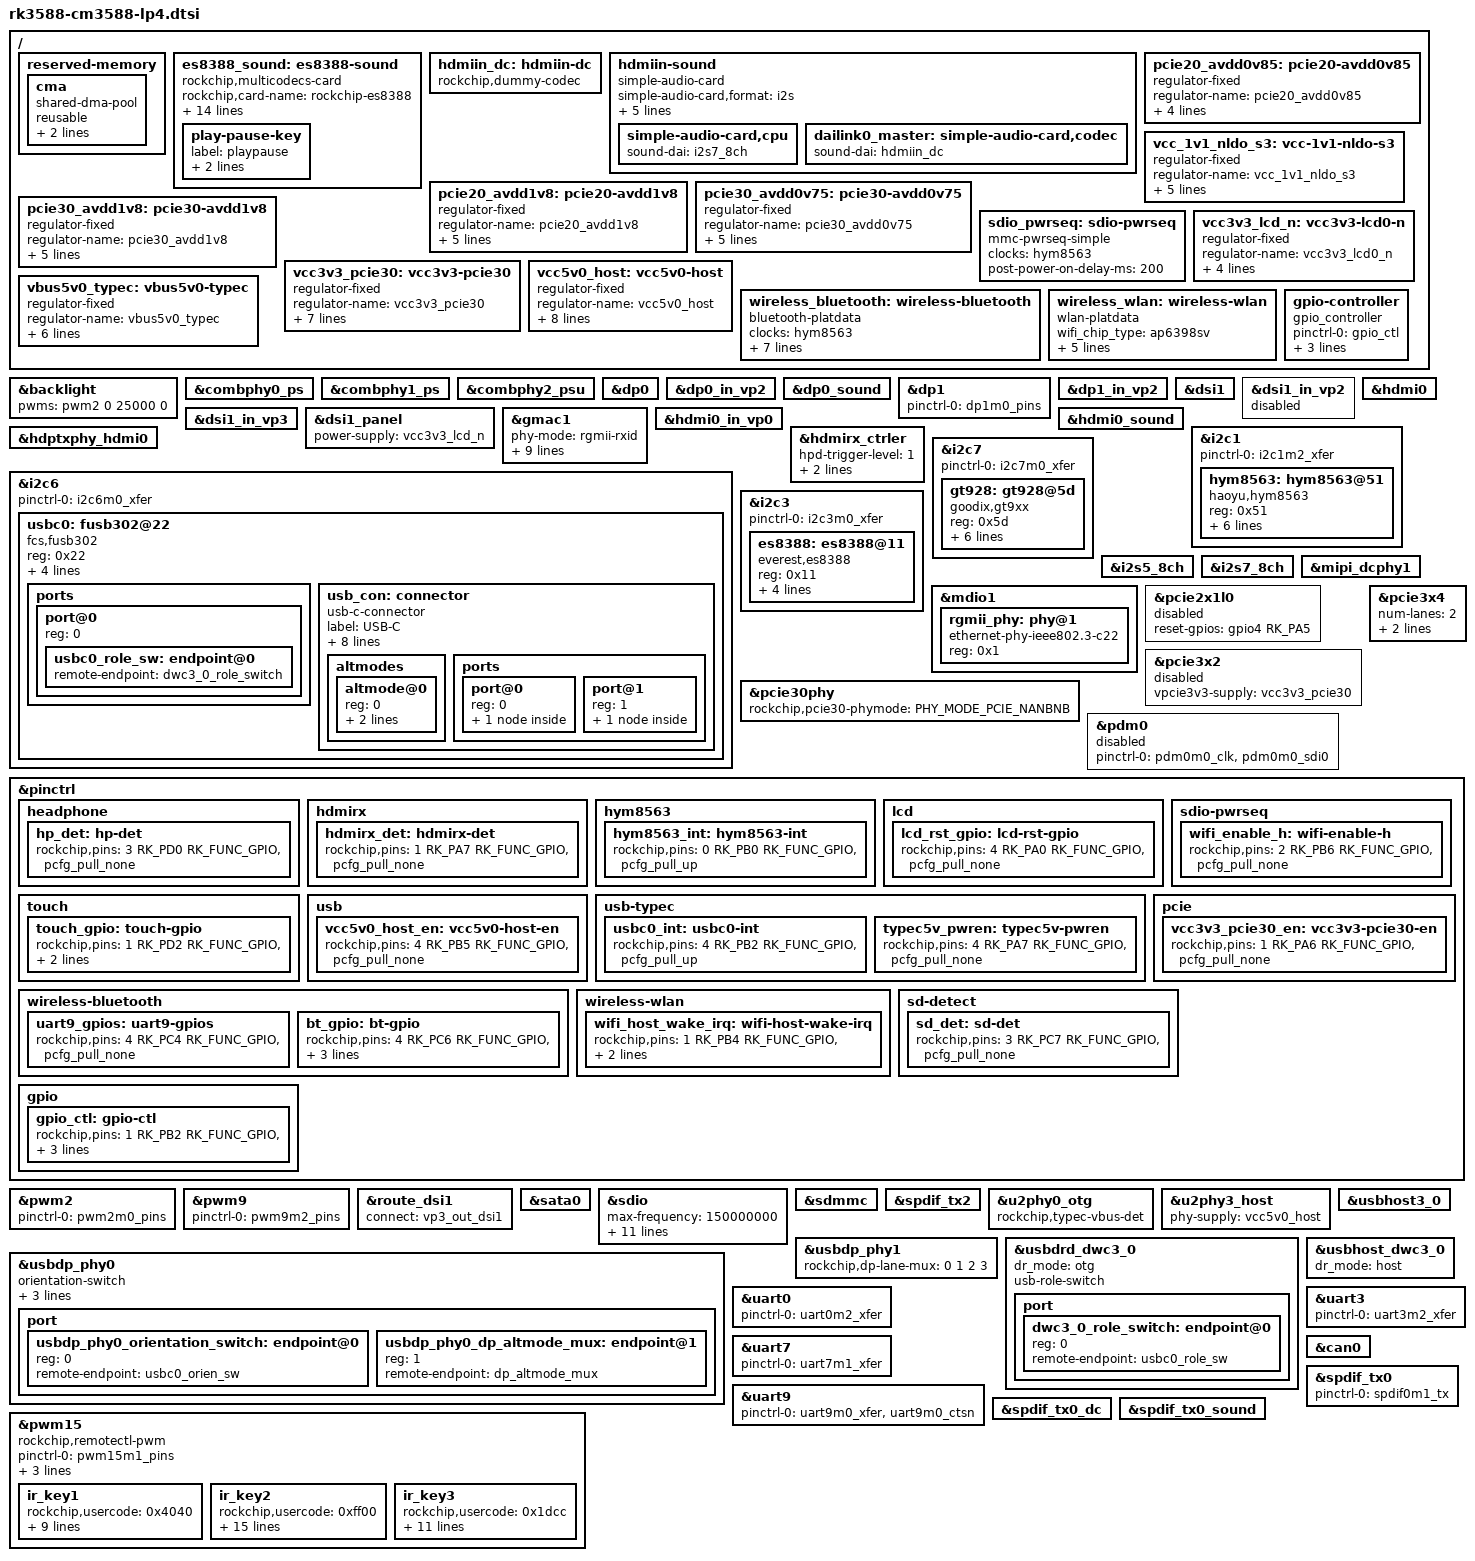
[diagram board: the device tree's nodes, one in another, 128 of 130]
// SPDX-License-Identifier: (GPL-2.0+ OR MIT)
/*
 * Copyright (c) 2021 Rockchip Electronics Co., Ltd.
 *
 */
#include "dt-bindings/usb/pd.h"
#include "rk3588.dtsi"
#include "rk3588-cm3588.dtsi"
#include "rk3588-cm3588-rk806-single.dtsi"

/ {
	/* If hdmirx node is disabled, delete the reserved-memory node here. */
	reserved-memory {
		#address-cells = <2>;
		#size-cells = <2>;
		ranges;

		/* Reserve 256MB memory for hdmirx-controller@fdee0000 */
		cma {
			compatible = "shared-dma-pool";
			reusable;
			reg = <0x0 (256 * 0x100000) 0x0 (256 * 0x100000)>;
			linux,cma-default;
		};
	};
	es8388_sound: es8388-sound {
		status = "okay";
		compatible = "rockchip,multicodecs-card";
		rockchip,card-name = "rockchip-es8388";
	//	hp-det-gpio = <&gpio3 RK_PD0 GPIO_ACTIVE_HIGH>;
		io-channels = <&saradc 5>;
		io-channel-names = "adc-detect";
		keyup-threshold-microvolt = <1800000>;
		poll-interval = <100>;
		//spk-con-gpio = <&gpio1 RK_PD3 GPIO_ACTIVE_HIGH>;
		//hp-con-gpio = <&gpio1 RK_PD2 GPIO_ACTIVE_HIGH>;
		rockchip,format = "i2s";
		rockchip,mclk-fs = <256>;
		rockchip,cpu = <&i2s0_8ch>;
		rockchip,codec = <&es8388>;
		rockchip,audio-routing =
			"Headphone", "LOUT1",
			"Headphone", "ROUT1",
			"Speaker", "LOUT2",
			"Speaker", "ROUT2",
			"Headphone", "Headphone Power",
			"Headphone", "Headphone Power",
			"Speaker", "Speaker Power",
			"Speaker", "Speaker Power",
			"LINPUT1", "Main Mic",
			"LINPUT2", "Main Mic",
			"RINPUT1", "Headset Mic",
			"RINPUT2", "Headset Mic";
	//	pinctrl-names = "default";
	//	pinctrl-0 = <&hp_det>;
		play-pause-key {
			label = "playpause";
			linux,code = <KEY_PLAYPAUSE>;
			press-threshold-microvolt = <2000>;
		};
	};

	hdmiin_dc: hdmiin-dc {
		compatible = "rockchip,dummy-codec";
		#sound-dai-cells = <0>;
	};

	hdmiin-sound {
		compatible = "simple-audio-card";
		simple-audio-card,format = "i2s";
		simple-audio-card,name = "rockchip,hdmiin";
		simple-audio-card,bitclock-master = <&dailink0_master>;
		simple-audio-card,frame-master = <&dailink0_master>;
		status = "okay";
		simple-audio-card,cpu {
			sound-dai = <&i2s7_8ch>;
		};
		dailink0_master: simple-audio-card,codec {
			sound-dai = <&hdmiin_dc>;
		};
	};
	pcie20_avdd0v85: pcie20-avdd0v85 {
		compatible = "regulator-fixed";
		regulator-name = "pcie20_avdd0v85";
		regulator-boot-on;
		regulator-always-on;
		regulator-min-microvolt = <850000>;
		regulator-max-microvolt = <850000>;
	//	vin-supply = <&avdd_0v85_s0>;
	};
	vcc_1v1_nldo_s3: vcc-1v1-nldo-s3 {
		compatible = "regulator-fixed";
		regulator-name = "vcc_1v1_nldo_s3";
		regulator-always-on;
		regulator-boot-on;
		regulator-min-microvolt = <1100000>;
		regulator-max-microvolt = <1100000>;
		vin-supply = <&vcc5v0_sys>;
	};
	pcie20_avdd1v8: pcie20-avdd1v8 {
		compatible = "regulator-fixed";
		regulator-name = "pcie20_avdd1v8";
		regulator-boot-on;
		regulator-always-on;
		regulator-min-microvolt = <1800000>;
		regulator-max-microvolt = <1800000>;
		vin-supply = <&avcc_1v8_s0>;
	};

	pcie30_avdd0v75: pcie30-avdd0v75 {
		compatible = "regulator-fixed";
		regulator-name = "pcie30_avdd0v75";
		regulator-boot-on;
		regulator-always-on;
		regulator-min-microvolt = <750000>;
		regulator-max-microvolt = <750000>;
		vin-supply = <&avdd_0v75_s0>;
	};

	pcie30_avdd1v8: pcie30-avdd1v8 {
		compatible = "regulator-fixed";
		regulator-name = "pcie30_avdd1v8";
		regulator-boot-on;
		regulator-always-on;
		regulator-min-microvolt = <1800000>;
		regulator-max-microvolt = <1800000>;
		vin-supply = <&avcc_1v8_s0>;
	};

	sdio_pwrseq: sdio-pwrseq {
		compatible = "mmc-pwrseq-simple";
		clocks = <&hym8563>;
		clock-names = "ext_clock";
		//pinctrl-names = "default";
		//pinctrl-0 = <&wifi_enable_h>;
		/*
		 * On the module itself this is one of these (depending
		 * on the actual card populated):
		 * - SDIO_RESET_L_WL_REG_ON
		 * - PDN (power down when low)
		 */
		post-power-on-delay-ms = <200>;
		//reset-gpios = <&gpio2 RK_PB6 GPIO_ACTIVE_LOW>;
	};

	vcc3v3_lcd_n: vcc3v3-lcd0-n {
		compatible = "regulator-fixed";
		regulator-name = "vcc3v3_lcd0_n";
		regulator-boot-on;
		enable-active-high;
		gpio = <&gpio1 RK_PC4 GPIO_ACTIVE_HIGH>;
		vin-supply = <&vcc_1v8_s0>;
	};

	vcc3v3_pcie30: vcc3v3-pcie30 {
		compatible = "regulator-fixed";
		regulator-name = "vcc3v3_pcie30";
		regulator-min-microvolt = <3300000>;
		regulator-max-microvolt = <3300000>;
		enable-active-high;
		gpios = <&gpio1 RK_PA6 GPIO_ACTIVE_HIGH>;
		startup-delay-us = <5000>;
		vin-supply = <&vcc12v_dcin>;
		pinctrl-names = "default";
		pinctrl-0 = <&vcc3v3_pcie30_en>;
	};

	vcc5v0_host: vcc5v0-host {
		compatible = "regulator-fixed";
		regulator-name = "vcc5v0_host";
		regulator-boot-on;
		regulator-always-on;
		regulator-min-microvolt = <5000000>;
		regulator-max-microvolt = <5000000>;
		enable-active-high;
		gpio = <&gpio4 RK_PB5 GPIO_ACTIVE_HIGH>;
		vin-supply = <&vcc5v0_usb>;
		pinctrl-names = "default";
		pinctrl-0 = <&vcc5v0_host_en>;
	};

	vbus5v0_typec: vbus5v0-typec {
		compatible = "regulator-fixed";
		regulator-name = "vbus5v0_typec";
		regulator-min-microvolt = <5000000>;
		regulator-max-microvolt = <5000000>;
		enable-active-high;
		gpio = <&gpio4 RK_PA7 GPIO_ACTIVE_HIGH>;
		vin-supply = <&vcc5v0_usb>;
		pinctrl-names = "default";
		pinctrl-0 = <&typec5v_pwren>;
	};

	wireless_bluetooth: wireless-bluetooth {
		compatible = "bluetooth-platdata";
		clocks = <&hym8563>;
		clock-names = "ext_clock";
		uart_rts_gpios = <&gpio4 RK_PC4 GPIO_ACTIVE_LOW>;
		pinctrl-names = "default", "rts_gpio";
		pinctrl-0 = <&uart9m0_rtsn>, <&bt_gpio>;
		pinctrl-1 = <&uart9_gpios>;
		BT,reset_gpio    = <&gpio4 RK_PC6 GPIO_ACTIVE_HIGH>;
		BT,wake_gpio     = <&gpio2 RK_PB6 GPIO_ACTIVE_HIGH>;
		BT,wake_host_irq = <&gpio2 RK_PC1 GPIO_ACTIVE_HIGH>;
		status = "okay";
	};

	wireless_wlan: wireless-wlan {
		compatible = "wlan-platdata";
		wifi_chip_type = "ap6398sv";//"ap6398s";
		pinctrl-names = "default";
		pinctrl-0 = <&wifi_host_wake_irq>;
		WIFI,host_wake_irq = <&gpio4 RK_PC2 GPIO_ACTIVE_HIGH>;
		WIFI,poweren_gpio = <&gpio1 RK_PB4 GPIO_ACTIVE_HIGH>;
		status = "okay";
	};

	gpio-controller{
		compatible = "gpio_controller";
		pinctrl-names = "default";
		pinctrl-0 = <&gpio_ctl>;
		mini4g_en = <&gpio1 RK_PB2 GPIO_ACTIVE_HIGH>;
		sata_en = <&gpio1 RK_PB3 GPIO_ACTIVE_HIGH>;
		fan_en = <&gpio3 RK_PD4 GPIO_ACTIVE_HIGH>;
		status = "okay";
	};
};

&backlight {
	pwms = <&pwm2 0 25000 0>;
	status = "okay";
};

&combphy0_ps {
	status = "okay";
};

&combphy1_ps {
	status = "okay";
};

&combphy2_psu {
	status = "okay";
};

&dp0 {
	//pinctrl-0 = <&dp0m2_pins>;
	pinctrl-names = "default";
	status = "okay";
};

&dp0_in_vp2 {
	status = "okay";
};

&dp0_sound {
	status = "okay";
};

&dp1 {
	pinctrl-0 = <&dp1m0_pins>;
	pinctrl-names = "default";
	status = "okay";
};

&dp1_in_vp2 {
	status = "okay";
};

/*
 * mipi_dcphy1 needs to be enabled
 * when dsi1 is enabled
 */
&dsi1 {
	status = "okay";
};

&dsi1_in_vp2 {
	status = "disabled";
};

&dsi1_in_vp3 {
	status = "okay";
};

&dsi1_panel {
	power-supply = <&vcc3v3_lcd_n>;
};

&gmac1 {
	/* Use rgmii-rxid mode to disable rx delay inside Soc */
	phy-mode = "rgmii-rxid";
	clock_in_out = "output";

	snps,reset-gpio = <&gpio0 RK_PC5 GPIO_ACTIVE_LOW>;
	snps,reset-active-low;
	/* Reset time is 20ms, 100ms for rtl8211f */
	snps,reset-delays-us = <0 20000 100000>;

	pinctrl-names = "default";
	pinctrl-0 = <&gmac1_miim
		     &gmac1_tx_bus2
		     &gmac1_rx_bus2
		     &gmac1_rgmii_clk
		     &gmac1_rgmii_bus>;

	tx_delay = <0x45>;
	/* rx_delay = <0x3f>; */

	phy-handle = <&rgmii_phy>;
	status = "okay";
};

&hdmi0 {
	//enable-gpios = <&gpio3 RK_PC5 GPIO_ACTIVE_HIGH>;
	status = "okay";
};

&hdmi0_in_vp0 {
	status = "okay";
};

&hdmi0_sound {
	status = "okay";
};


&hdptxphy_hdmi0 {
	status = "okay";
};

/* Should work with at least 128MB cma reserved above. */
&hdmirx_ctrler {
	status = "okay";

	/* Effective level used to trigger HPD: 0-low, 1-high */
	hpd-trigger-level = <1>;
	hdmirx-det-gpios = <&gpio1 RK_PA7 GPIO_ACTIVE_LOW>;
	pinctrl-names = "default";
	pinctrl-0 = <&hdmirx_det>;
};

&i2c1 {
	status = "okay";
	pinctrl-names = "default";
	pinctrl-0 = <&i2c1m2_xfer>;

	hym8563: hym8563@51 {
	status = "okay";
		compatible = "haoyu,hym8563";
		reg = <0x51>;
		#clock-cells = <0>;
		clock-frequency = <32768>;
		clock-output-names = "hym8563";
		pinctrl-names = "default";
		pinctrl-0 = <&hym8563_int>;
		interrupt-parent = <&gpio0>;
		interrupts = <RK_PB0 IRQ_TYPE_LEVEL_LOW>;
		wakeup-source;
	};
};

&i2c6 {
	status = "okay";
	pinctrl-names = "default";
	pinctrl-0 = <&i2c6m0_xfer>;
	usbc0: fusb302@22 {
		compatible = "fcs,fusb302";
		reg = <0x22>;
		interrupt-parent = <&gpio4>;
		interrupts = <RK_PB2 IRQ_TYPE_LEVEL_LOW>;
		pinctrl-names = "default";
		pinctrl-0 = <&usbc0_int>;
		vbus-supply = <&vbus5v0_typec>;
		status = "okay";

		ports {
			#address-cells = <1>;
			#size-cells = <0>;

			port@0 {
				reg = <0>;
				usbc0_role_sw: endpoint@0 {
					remote-endpoint = <&dwc3_0_role_switch>;
				};
			};
		};

		usb_con: connector {
			compatible = "usb-c-connector";
			label = "USB-C";
			data-role = "dual";
			power-role = "dual";
			try-power-role = "sink";
			op-sink-microwatt = <1000000>;
			sink-pdos = <PDO_FIXED(5000, 1000, PDO_FIXED_USB_COMM)>;
			source-pdos = <PDO_FIXED(5000, 3000, PDO_FIXED_USB_COMM)>;

			altmodes {
				#address-cells = <1>;
				#size-cells = <0>;

				altmode@0 {
					reg = <0>;
					svid = <0xff01>;
					vdo = <0xffffffff>;
				};
			};

			ports {
				#address-cells = <1>;
				#size-cells = <0>;

				port@0 {
					reg = <0>;
					usbc0_orien_sw: endpoint {
						remote-endpoint = <&usbdp_phy0_orientation_switch>;
					};
				};

				port@1 {
					reg = <1>;
					dp_altmode_mux: endpoint {
						remote-endpoint = <&usbdp_phy0_dp_altmode_mux>;
					};
				};
			};
		};
	};
};

&i2c7 {
	status = "okay";
	pinctrl-names = "default";
	pinctrl-0 = <&i2c7m0_xfer>;

		gt928: gt928@5d {
		status = "okay";
		compatible = "goodix,gt9xx";
		reg = <0x5d>;
		max-x = <1280>;
		max-y = <800>;
		tp-size = <89>;
		pinctrl-names = "default";
		pinctrl-0 = <&touch_gpio>;
		touch-gpio = <&gpio1 RK_PD3 GPIO_ACTIVE_LOW>;
		reset-gpio = <&gpio1 RK_PD2 GPIO_ACTIVE_LOW>;
	};
};

&i2c3 {
	status = "okay";
	pinctrl-names = "default";
	pinctrl-0 = <&i2c3m0_xfer>;

	es8388: es8388@11 {
		status = "okay";
		#sound-dai-cells = <0>;
		compatible = "everest,es8388", "everest,es8323";
		reg = <0x11>;
		clocks = <&cru I2S0_8CH_MCLKOUT>;
		clock-names = "mclk";
		assigned-clocks = <&cru I2S0_8CH_MCLKOUT>;
		assigned-clock-rates = <12288000>;
		pinctrl-names = "default";
		pinctrl-0 = <&i2s0_mclk>;
	};

};

&i2s5_8ch {
	status = "okay";
};

&i2s7_8ch {
	status = "okay";
};

&mdio1 {
	rgmii_phy: phy@1 {
		compatible = "ethernet-phy-ieee802.3-c22";
		reg = <0x1>;
	};
};

&mipi_dcphy1 {
	status = "okay";
};


&pcie2x1l0 {
	reset-gpios = <&gpio4 RK_PA5 GPIO_ACTIVE_HIGH>;
	status = "disabled";
};

&pcie30phy {
	rockchip,pcie30-phymode = <PHY_MODE_PCIE_NANBNB>;
	status = "okay";
};

&pcie3x2 {
	//reset-gpios = <&gpio4 RK_PB6 GPIO_ACTIVE_HIGH>;
	vpcie3v3-supply = <&vcc3v3_pcie30>;
	status = "disabled";
};

&pcie3x4 {
	num-lanes = <2>;
	//reset-gpios = <&gpio4 RK_PB6 GPIO_ACTIVE_HIGH>;
	reset-gpios = <&gpio3 RK_PC6 GPIO_ACTIVE_HIGH>;
	vpcie3v3-supply = <&vcc3v3_pcie30>;
	status = "okay";
};

&pdm0 {
	status = "disabled";
	pinctrl-names = "default";
	pinctrl-0 = <&pdm0m0_clk
		     &pdm0m0_sdi0>;
};

&pinctrl {
	headphone {
		hp_det: hp-det {
			rockchip,pins = <3 RK_PD0 RK_FUNC_GPIO &pcfg_pull_none>;
		};
	};
	hdmirx{
		hdmirx_det: hdmirx-det{
			rockchip,pins = <1 RK_PA7 RK_FUNC_GPIO &pcfg_pull_none>;
			};
	};
	hym8563 {
		hym8563_int: hym8563-int {
			rockchip,pins = <0 RK_PB0 RK_FUNC_GPIO &pcfg_pull_up>;
		};
	};

	lcd {
		lcd_rst_gpio: lcd-rst-gpio {
			rockchip,pins = <4 RK_PA0 RK_FUNC_GPIO &pcfg_pull_none>;
		};
	};

	sdio-pwrseq {
		wifi_enable_h: wifi-enable-h {
		       rockchip,pins = <2 RK_PB6 RK_FUNC_GPIO &pcfg_pull_none>;
	       };
	};

	touch {
		touch_gpio: touch-gpio {
			rockchip,pins =
				<1 RK_PD2 RK_FUNC_GPIO &pcfg_pull_up>,
				<1 RK_PD3 RK_FUNC_GPIO &pcfg_pull_none>;
		};
	};

	usb {
		vcc5v0_host_en: vcc5v0-host-en {
			rockchip,pins = <4 RK_PB5 RK_FUNC_GPIO &pcfg_pull_none>;
		};
	};
	usb-typec {
		usbc0_int: usbc0-int {
			rockchip,pins = <4 RK_PB2 RK_FUNC_GPIO &pcfg_pull_up>;
		};

		typec5v_pwren: typec5v-pwren {
			rockchip,pins = <4 RK_PA7 RK_FUNC_GPIO &pcfg_pull_none>;
		};
	};

	pcie {
		vcc3v3_pcie30_en: vcc3v3-pcie30-en {
			rockchip,pins = <1 RK_PA6 RK_FUNC_GPIO &pcfg_pull_none>;
		};
	};

	wireless-bluetooth {
		uart9_gpios: uart9-gpios {
			rockchip,pins = <4 RK_PC4 RK_FUNC_GPIO &pcfg_pull_none>;
		};

		bt_gpio: bt-gpio {
			rockchip,pins =
				<4 RK_PC6 RK_FUNC_GPIO &pcfg_pull_none>,
				<2 RK_PB6 RK_FUNC_GPIO &pcfg_pull_up>,
				<2 RK_PC1 RK_FUNC_GPIO &pcfg_pull_down>;
		};
	};

	wireless-wlan {
		wifi_host_wake_irq: wifi-host-wake-irq {
			rockchip,pins =
				<1 RK_PB4 RK_FUNC_GPIO &pcfg_pull_up>,
				<4 RK_PC2 RK_FUNC_GPIO &pcfg_pull_down>;
		};
	};

	sd-detect {
		sd_det: sd-det {
		       rockchip,pins = <3 RK_PC7 RK_FUNC_GPIO &pcfg_pull_none>;
	       };
	};

	gpio {
		gpio_ctl: gpio-ctl {
			rockchip,pins =
				<1 RK_PB2 RK_FUNC_GPIO &pcfg_pull_up>,
				<3 RK_PD4 RK_FUNC_GPIO &pcfg_pull_up>,
				<1 RK_PB3 RK_FUNC_GPIO &pcfg_pull_up>;
		};
	};
};

&pwm2 {
	status = "okay";
	pinctrl-0 = <&pwm2m0_pins>;
};

&pwm9 {
	pinctrl-0 = <&pwm9m2_pins>;
	status = "okay";
};

&route_dsi1 {
	status = "okay";
	connect = <&vp3_out_dsi1>;
};

&sata0 {
	status = "okay";
};

&sdio {
	max-frequency = <150000000>;
	no-sd;
	no-mmc;
	bus-width = <4>;
	disable-wp;
	cap-sd-highspeed;
	cap-sdio-irq;
	keep-power-in-suspend;
	mmc-pwrseq = <&sdio_pwrseq>;
	non-removable;
	pinctrl-names = "default";
	pinctrl-0 = <&sdiom0_pins>;
	sd-uhs-sdr104;
	status = "okay";
};

&sdmmc {
	status = "okay";
//	vmmc-supply = <&vcc_3v3_sd_s0>;
/*	pinctrl-names = "default";
	pinctrl-0 = <&sd_det &sdmmc_clk &sdmmc_cmd &sdmmc_det &sdmmc_bus4>;
	cd-gpios = <&gpio3 RK_PC7 GPIO_ACTIVE_LOW>;
	cd-inverted;*/
};

&spdif_tx2 {
	status = "okay";
};

&u2phy0_otg {
	rockchip,typec-vbus-det;
};

&u2phy3_host {
	phy-supply = <&vcc5v0_host>;
};

/*&usbdp_phy0 {
	rockchip,dp-lane-mux = <2 3>;
};
*/
&usbdp_phy0 {
	orientation-switch;
	svid = <0xff01>;
	sbu1-dc-gpios = <&gpio0 RK_PC6 GPIO_ACTIVE_HIGH>;
	sbu2-dc-gpios = <&gpio0 RK_PD3 GPIO_ACTIVE_HIGH>;

	port {
		#address-cells = <1>;
		#size-cells = <0>;
		usbdp_phy0_orientation_switch: endpoint@0 {
			reg = <0>;
			remote-endpoint = <&usbc0_orien_sw>;
		};

		usbdp_phy0_dp_altmode_mux: endpoint@1 {
			reg = <1>;
			remote-endpoint = <&dp_altmode_mux>;
		};
	};
};

&usbdp_phy1 {
	rockchip,dp-lane-mux = <0 1 2 3>;
};

&usbdrd_dwc3_0 {
	dr_mode = "otg";
	usb-role-switch;
	port {
		#address-cells = <1>;
		#size-cells = <0>;
		dwc3_0_role_switch: endpoint@0 {
			reg = <0>;
			remote-endpoint = <&usbc0_role_sw>;
		};
	};
};

&usbhost3_0 {
	status = "okay";
};

&usbhost_dwc3_0 {
	dr_mode = "host";
	status = "okay";
};

&uart0 {
	status = "okay";
	pinctrl-names = "default";
	pinctrl-0 = <&uart0m2_xfer>;
};

&uart3 {
	status = "okay";
	pinctrl-names = "default";
	pinctrl-0 = <&uart3m2_xfer>;
};

&uart7 {
	status = "okay";
	pinctrl-names = "default";
	pinctrl-0 = <&uart7m1_xfer>;
};

&uart9 {
	status = "okay";
	pinctrl-names = "default";
	pinctrl-0 = <&uart9m0_xfer &uart9m0_ctsn>;
};

&can0 {
	status = "okay";
};

&vcc3v3_lcd_n {
	gpio = <&gpio1 RK_PC4 GPIO_ACTIVE_HIGH>;
	enable-active-high;
};

&spdif_tx0 {
	status = "okay";
	pinctrl-names = "default";
	pinctrl-0 = <&spdif0m1_tx>;
};

&spdif_tx0_dc {
	status = "okay";
};

&spdif_tx0_sound {
	status = "okay";
};

&pwm15 {
	compatible = "rockchip,remotectl-pwm";
	pinctrl-names = "default";
	pinctrl-0 = <&pwm15m1_pins>;
	remote_pwm_id = <15>;
	handle_cpu_id = <1>;
	remote_support_psci = <0>;
	status = "okay";

	ir_key1 {
		rockchip,usercode = <0x4040>;
		rockchip,key_table =
			<0xf2	KEY_REPLY>,
			<0xba	KEY_BACK>,
			<0xf4	KEY_UP>,
			<0xf1	KEY_DOWN>,
			<0xef	KEY_LEFT>,
			<0xee	KEY_RIGHT>,
			<0xbd	KEY_HOME>,
			<0xea	KEY_VOLUMEUP>,
			<0xe3	KEY_VOLUMEDOWN>,
			<0xe2	KEY_SEARCH>,
			<0xb2	KEY_POWER>,
			<0xbc	KEY_MUTE>,
			<0xec	KEY_MENU>,
			<0xbf	0x190>,
			<0xe0	0x191>,
			<0xe1	0x192>,
			<0xe9	183>,
			<0xe6	248>,
			<0xe8	185>,
			<0xe7	186>,
			<0xf0	388>,
			<0xbe	0x175>;
	};

	ir_key2 {
		rockchip,usercode = <0xff00>;
		rockchip,key_table =
			<0xf9	KEY_HOME>,
			<0xbf	KEY_BACK>,
			<0xfb	KEY_MENU>,
			<0xaa	KEY_REPLY>,
			<0xb9	KEY_UP>,
			<0xe9	KEY_DOWN>,
			<0xb8	KEY_LEFT>,
			<0xea	KEY_RIGHT>,
			<0xeb	KEY_VOLUMEDOWN>,
			<0xef	KEY_VOLUMEUP>,
			<0xf7	KEY_MUTE>,
			<0xe7	KEY_POWER>,
			<0xfc	KEY_POWER>,
			<0xa9	KEY_VOLUMEDOWN>,
			<0xa8	KEY_PLAYPAUSE>,
			<0xe0	KEY_VOLUMEDOWN>,
			<0xa5	KEY_VOLUMEDOWN>,
			<0xab	183>,
			<0xb7	388>,
			<0xe8	388>,
			<0xf8	184>,
			<0xaf	185>,
			<0xed	KEY_VOLUMEDOWN>,
			<0xee	186>,
			<0xb3	KEY_VOLUMEDOWN>,
			<0xf1	KEY_VOLUMEDOWN>,
			<0xf2	KEY_VOLUMEDOWN>,
			<0xf3	KEY_SEARCH>,
			<0xb4	KEY_VOLUMEDOWN>,
			<0xa4	KEY_SETUP>,
			<0xbe	KEY_SEARCH>;
	};

	ir_key3 {
		rockchip,usercode = <0x1dcc>;
		rockchip,key_table =
			<0xee	KEY_REPLY>,
			<0xf0	KEY_BACK>,
			<0xf8	KEY_UP>,
			<0xbb	KEY_DOWN>,
			<0xef	KEY_LEFT>,
			<0xed	KEY_RIGHT>,
			<0xfc	KEY_HOME>,
			<0xf1	KEY_VOLUMEUP>,
			<0xfd	KEY_VOLUMEDOWN>,
			<0xb7	KEY_SEARCH>,
			<0xff	KEY_POWER>,
			<0xf3	KEY_MUTE>,
			<0xbf	KEY_MENU>,
			<0xf9	0x191>,
			<0xf5	0x192>,
			<0xb3	388>,
			<0xbe	KEY_1>,
			<0xba	KEY_2>,
			<0xb2	KEY_3>,
			<0xbd	KEY_4>,
			<0xf9	KEY_5>,
			<0xb1	KEY_6>,
			<0xfc	KEY_7>,
			<0xf8	KEY_8>,
			<0xb0	KEY_9>,
			<0xb6	KEY_0>,
			<0xb5	KEY_BACKSPACE>;
	};
};
